AUTOSAR XML (schema 4-2-2)
package /Components
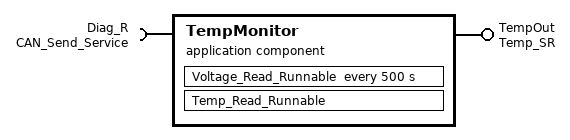
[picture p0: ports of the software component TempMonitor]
  application sw component type TempMonitor
    provide port TempOut: provided-interface=Temp_SR
    require port Diag_R: required-interface=CAN_Send_Service
    behavior TempMonitorBehavior
      init event Temp_Init: start-on-event=Voltage_Read_Runnable
      timing event Temp_Timer: start-on-event=Voltage_Read_Runnable, period=500
      runnable Temp_Read_Runnable: minimum-start-interval=500, symbol=TempMonitor_Temp_Read_Runnable
        data-send-points:
          access Temp_VarAccess: accessed-variable=TempOut.Temp_Celsius
